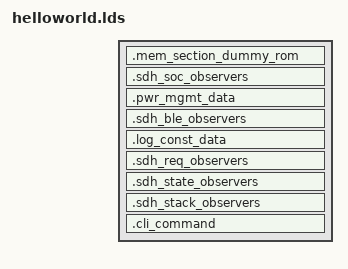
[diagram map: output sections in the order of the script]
SECTIONS
{
  .mem_section_dummy_rom :
  {
  }
  .sdh_soc_observers :
  {
    PROVIDE(__start_sdh_soc_observers = .);
    KEEP(*(SORT(.sdh_soc_observers*)))
    PROVIDE(__stop_sdh_soc_observers = .);
  } > FLASH
  .pwr_mgmt_data :
  {
    PROVIDE(__start_pwr_mgmt_data = .);
    KEEP(*(SORT(.pwr_mgmt_data*)))
    PROVIDE(__stop_pwr_mgmt_data = .);
  } > FLASH
  .sdh_ble_observers :
  {
    PROVIDE(__start_sdh_ble_observers = .);
    KEEP(*(SORT(.sdh_ble_observers*)))
    PROVIDE(__stop_sdh_ble_observers = .);
  } > FLASH
  .log_const_data :
  {
    PROVIDE(__start_log_const_data = .);
    KEEP(*(SORT(.log_const_data*)))
    PROVIDE(__stop_log_const_data = .);
  } > FLASH
  .sdh_req_observers :
  {
    PROVIDE(__start_sdh_req_observers = .);
    KEEP(*(SORT(.sdh_req_observers*)))
    PROVIDE(__stop_sdh_req_observers = .);
  } > FLASH
  .sdh_state_observers :
  {
    PROVIDE(__start_sdh_state_observers = .);
    KEEP(*(SORT(.sdh_state_observers*)))
    PROVIDE(__stop_sdh_state_observers = .);
  } > FLASH
  .sdh_stack_observers :
  {
    PROVIDE(__start_sdh_stack_observers = .);
    KEEP(*(SORT(.sdh_stack_observers*)))
    PROVIDE(__stop_sdh_stack_observers = .);
  } > FLASH
    .cli_command :
  {
    PROVIDE(__start_cli_command = .);
    KEEP(*(.cli_command))
    PROVIDE(__stop_cli_command = .);
  } > FLASH
  
INCLUDE "dump/nRF5_SDK_14.2.0_17b948a/components/softdevice/s112/toolchain/armgcc/armgcc_s112_nrf52810_xxaa.ld"
